# SR_MPU register map
Vendor: Texas Instruments
Peripheral module from a debugger description file (folder omap4430).
Registers are 32-bit, access per field, reset 0x0 unless marked. A register's access mark holds for its fields unless they carry their own. Offsets are as the file gives them; lines under a group give offsets from that group; [hi:lo] are bit positions; {n}, {i} and the like mark numbered series; 'fields as' and 'values as' point back to an identical list; <NAME> marks a mode.

## SR_MPU
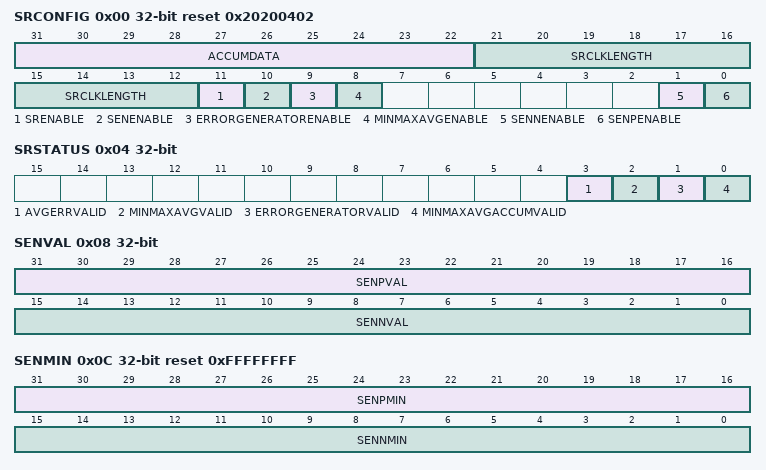
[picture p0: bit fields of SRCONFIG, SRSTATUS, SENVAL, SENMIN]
0x00 SRCONFIG rw reset 0x20200402 — Configuration bits for the Sensor Core and the Digital Processing.
  [31:22] ACCUMDATA — Number of Values to Accumulate
  [21:12] SRCLKLENGTH — Determines frequency of SRClk
  [11] SRENABLE — 0: Asynchronously resets MinMaxAvgAccumValid, MinMaxAvgValid, ErrorGeneratorValid, AccumData sensor, SRClk counter, and MinMaxAvg registers. Also gates the clock for power savings and disables all the digital logic. , 1: Enables the module
  [10] SENENABLE — 0: All sensors disabled, 1: Sensors enabled per SenNEnable and SenPEnable
  [9] ERRORGENERATORENABLE — 0: Error Generator Module disabled, 1: Error Generator Module enabled
  [8] MINMAXAVGENABLE — 0: MinMaxAvg Detector Module disabled, 1: MinMaxAvg Detector Module enabled
  [1] SENNENABLE — 0: Disable SenN sensor, 1: Enable SenN sensor
  [0] SENPENABLE — 0: Disable SenP sensor, 1: Enable SenP sensor
0x04 SRSTATUS ro — Status bits that indicate that the values in the register are valid or events have occurred.
  [3] AVGERRVALID — 0: AvgError registers are not valid, 1: AvgError registers are valid.
  [2] MINMAXAVGVALID — 0: SenVal, SenMin, SenMax, SenAvg registers are not valid, 1: SenVal, SenMin, SenMax, SenAvg registers are valid, but not necessarily fully accumulated
  [1] ERRORGENERATORVALID — 0: SenError register do not have valid data, 1: SenError registers have valid data.
  [0] MINMAXAVGACCUMVALID — 0: SenVal, SenMin, SenMax, SenAvg registers are not valid, 1: SenVal, SenMin, SenMax, SenAvg registers have valid, final data
0x08 SENVAL ro — The current sensor values from the Sensor Core.
  [31:16] SENPVAL — The latest value of the SenPVal from the sensor core.
  [15:0] SENNVAL — The latest value of the SenNVal from the sensor core.
0x0C SENMIN ro reset 0xFFFFFFFF — The minimum sensor values.
  [31:16] SENPMIN — The minimum value of the SenPVal from the sensor core since the last restat operation.
  [15:0] SENNMIN — The minimum value of the SenNVal from the sensor core since the last restat operation.
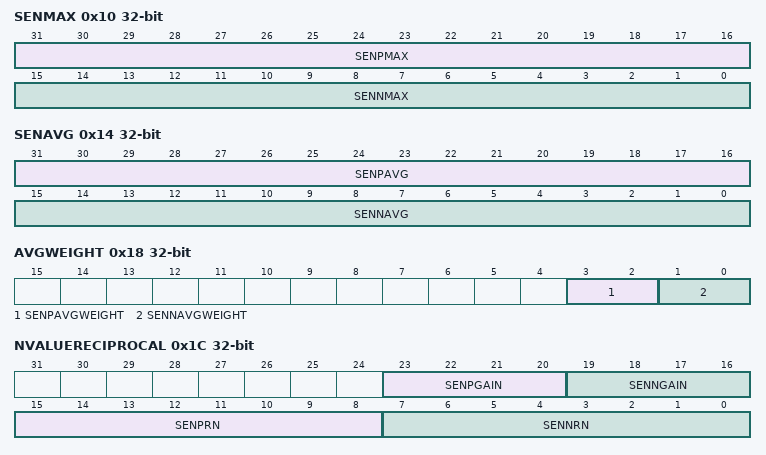
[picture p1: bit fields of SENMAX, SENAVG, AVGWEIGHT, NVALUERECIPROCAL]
0x10 SENMAX ro — The maximum sensor values.
  [31:16] SENPMAX — The maximum value of the SenPVal from the sensor core since the last restat operation.
  [15:0] SENNMAX — The maximum value of the SenNVal from the sensor core since the last restat operation.
0x14 SENAVG ro — The average sensor values.
  [31:16] SENPAVG — The running average of the SenPVal from the sensor core since the last restat operation.
  [15:0] SENNAVG — The running average of the SenNVal from the sensor core since the last restat operation.
0x18 AVGWEIGHT — The weighting factor in the average computation.
  [3:2] SENPAVGWEIGHT rw — The weighting factor for the SenP averager.
  [1:0] SENNAVGWEIGHT rw — The weighting factor for the SenN averager.
0x1C NVALUERECIPROCAL — The reciprocal of the SenN and SenP values used in error generation.
  [23:20] SENPGAIN rw — The gain value for the SenP reciprocal.
  [19:16] SENNGAIN rw — The gain value for the SenN reciprocal.
  [15:8] SENPRN rw — The scale value for the SenP reciprocal.
  [7:0] SENNRN rw — The scale value for the SenN reciprocal.
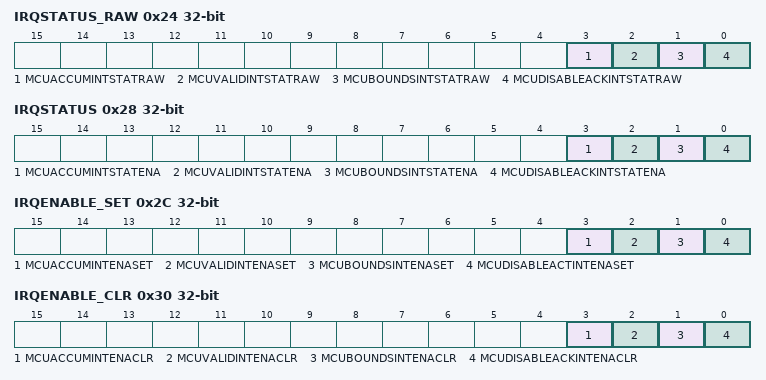
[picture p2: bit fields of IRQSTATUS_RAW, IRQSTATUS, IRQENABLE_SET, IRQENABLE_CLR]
0x24 IRQSTATUS_RAW — MCU raw interrup status and set.
  [3] MCUACCUMINTSTATRAW rw — 0: Accum interrupt status is unchanged 1: Accum interrupt status is set
  [2] MCUVALIDINTSTATRAW rw — 0: Valid interrupt status is unchanged 1: Valid interrupt status is set
  [1] MCUBOUNDSINTSTATRAW rw — 0: Bounds interrupt status is unchanged 1: Bounds interrupt status is set
  [0] MCUDISABLEACKINTSTATRAW rw — 0: MCUDisable acknowledge status is unchanged 1: MCUDisable acknowledge status is set
0x28 IRQSTATUS — MCU masked interrupt status and clear.
  [3] MCUACCUMINTSTATENA rw — Read 0: Accum interrupt status is unchanged.
    1=MCUACCUMINTSTATENA_1_r (Accum interrupt status is set.); 0=MCUACCUMINTSTATENA_0_w (Accum interrupt status is unchanged.); 1=MCUACCUMINTSTATENA_1_w (Accum interrupt status is cleared.)
  [2] MCUVALIDINTSTATENA rw — Read 0: Valid interrupt status is unchanged.
    1=MCUVALIDINTSTATENA_1_r (Valid interrupt status is set.); 0=MCUVALIDINTSTATENA_0_w (Valid interrupt status is unchanged.); 1=MCUVALIDINTSTATENA_1_w (Valid interrupt status is cleared.)
  [1] MCUBOUNDSINTSTATENA rw — Read 0: Bounds interrupt status is unchanged.
    1=MCUBOUNDSINTSTATENA_1_r (Bounds interrupt status is set.); 0=MCUBOUNDSINTSTATENA_0_w (Bounds interrupt status is unchanged.); 1=MCUBOUNDSINTSTATENA_1_w (Bounds interrupt status is cleared.)
  [0] MCUDISABLEACKINTSTATENA rw — Read 0: MCUDisable acknowledge status is unchanged.
    1=MCUDISABLEACKINTSTATENA_1_r (MCUDisable acknowledge status is set.); 0=MCUDISABLEACKINTSTATENA_0_w (MCUDisable interrupt status is unchanged.); 1=MCUDISABLEACKINTSTATENA_1_w (MCUDisable interrupt status is cleared.)
0x2C IRQENABLE_SET — MCU interrupt enable flag and set.
  [3] MCUACCUMINTENASET rw — Read mode: 0: Accum interrupt generation is disabled/masked, 1: Accum interrupt generation is enabled; Write mode: 0: No change to Accum interrupt enable, 1: Enable Accum interrupt generation.
  [2] MCUVALIDINTENASET rw — Read mode: 0: Valid interrupt generation is disabled/masked, 1: Valid interrupt generation is enabled; Write mode: 0: No change to Valid interrupt enable, 1: Enable Valid interrupt generation.
  [1] MCUBOUNDSINTENASET rw — Read mode: 0: Bounds interrupt generation is disabled/masked, 1: Bounds interrupt generation is enabled; Write mode: 0: No change to Bounds interrupt enable, 1: Enable Bounds interrupt generation.
  [0] MCUDISABLEACTINTENASET rw — Read mode: 0: MCUDisableAck interrupt generation is disabled/masked, 1: MCUDisableAck interrupt generation is enabled; Write mode: 0: No change to MCUDisAck interrupt enable, 1: Enable MCUDisableAck interrupt generation.
0x30 IRQENABLE_CLR — MCU interrup enable flag and clear.
  [3] MCUACCUMINTENACLR rw — Read mode: 0: Accum interrupt generation is disabled/masked, 1: Accum interrupt generation is enabled; Write mode: 0: No change to Accum interrupt enable, 1: Enable Accum interrupt generation.
  [2] MCUVALIDINTENACLR rw — Read mode: 0: Valid interrupt generation is disabled/masked, 1: Valid interrupt generation is enabled; Write mode: 0: No change to Valid interrupt enable, 1: Enable Valid interrupt generation.
  [1] MCUBOUNDSINTENACLR rw — Read mode: 0: Bounds interrupt generation is disabled/masked, 1: Bounds interrupt generation is enabled; Write mode: 0: No change to Bounds interrupt enable, 1: Enable Bounds interrupt generation.
  [0] MCUDISABLEACKINTENACLR rw — Read mode: 0: MCUDisableAck interrupt generation is disabled/masked, 1: MCUDisableAck interrupt generation is enabled; Write mode: 0: No change to MCUDisAck interrupt enable, 1: Enable MCUDisableAck interrupt generation.
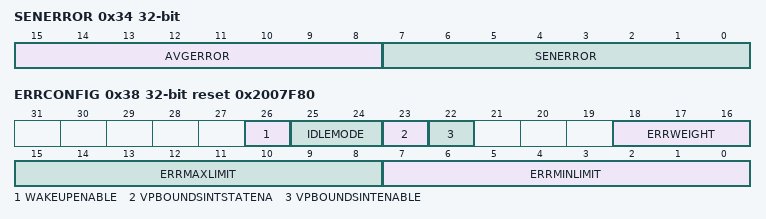
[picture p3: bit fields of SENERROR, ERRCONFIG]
0x34 SENERROR ro — The sensor error from the error generator.
  [15:8] AVGERROR — The average sensor error.
  [7:0] SENERROR — The percentage of sensor error.
0x38 ERRCONFIG reset 0x2007F80 — The sensor error configuration.
  [26] WAKEUPENABLE rw — Wakeup from MCU Interrupts enable.
  [25:24] IDLEMODE rw — 0b00: Force-Idle Mode, 0b01: No Idle Mode, 0b10: Smart-Idle Mode #2, 0b11: Smart-Idle-Wkup mode
  [23] VPBOUNDSINTSTATENA rw — 0: Bounds interrupt status is unchanged, 1: Bounds interrupt status is cleared.
  [22] VPBOUNDSINTENABLE rw — 0: Bounds interrupt disabled, 1: Bounds interrupt enabled.
  [18:16] ERRWEIGHT rw — The AvgSenError weight.
  [15:8] ERRMAXLIMIT rw — The upper limit of SenError for interrupt generation.
  [7:0] ERRMINLIMIT rw — The lower limit of SenError for interrupt generation.
